VERSION ""
//Author: Matthew Nice

NS_ :

BS_:

BU_: XXX

BO_ 116 PEDAL_CMD: 12 XXX
 SG_ TORQUE_CMD_CCM : 86|12@0+ (1,0) [0|4000] "" XXX
 SG_ ACCEL_THROTTLE : 43|10@0+ (1,0) [0|4000] "" XXX
 SG_ ACCEL_PEDAL_DRIVER : 49|10@0+ (1,0) [0|4000] "" XXX

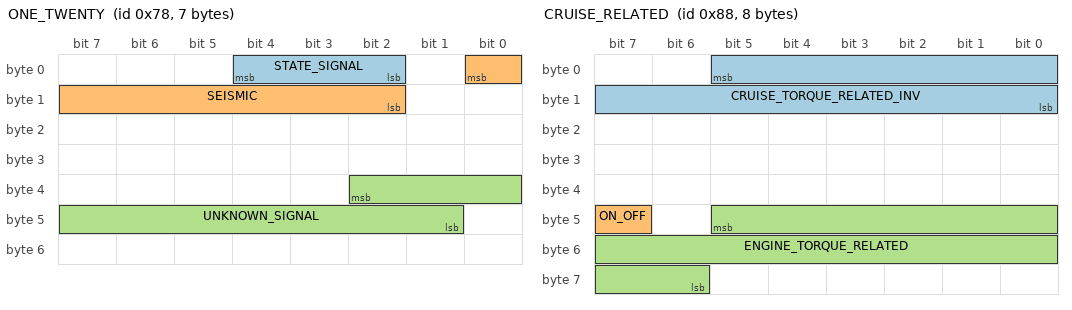
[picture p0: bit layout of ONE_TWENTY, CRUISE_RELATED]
BO_ 120 ONE_TWENTY: 7 XXX
 SG_ STATE_SIGNAL : 4|3@0+ (1,0) [0|4000] "" XXX
 SG_ SEISMIC : 0|7@0+ (1,0) [0|4000] "" XXX
 SG_ UNKNOWN_SIGNAL : 34|10@0+ (1,0) [0|4000] "" XXX

BO_ 136 CRUISE_RELATED: 8 XXX
 SG_ CRUISE_TORQUE_RELATED_INV : 5|14@0+ (1,0) [0|4000] "" XXX
 SG_ ON_OFF : 47|1@0+ (1,0) [0|1] "" XXX
 SG_ ENGINE_TORQUE_RELATED : 45|16@0+ (1,0) [0|50000] "" XXX

BO_ 139 STEER_ANGLE: 48 XXX
 SG_ STEER_ANGLE : 55|16@0+ (0.05,0) [0|500] "" XXX
 SG_ STEER_ANGLE_REPEAT : 208|16@0+ (0.05,0) [0|500] "" XXX

BO_ 140 PEDAL_THROTTLE: 48 XXX
 SG_ ACCEL_PEDAL_POSITION: 43|10@0+ (1,0) [0|1000] "" XXX
 SG_ ACCEL_PEDAL_POSITION_REPEAT: 49|10@0+ (1,0) [0|200] "" XXX
 SG_ RPM_RELATED: 86|12@0+ (0.05,0) [0|4000] "" XXX
 SG_ WHEEL_TORQUE_CMD_RELATED: 139|16@0+ (0.05,0) [0|100000] "" XXX
 SG_ RPM: 167|16@0+ (0.14285,0) [0|100000] "" XXX
 SG_ WHEEL_TORQUE_CMD_RELATED_2: 183|10@0+ (0.05,0) [0|100000] "" XXX

BO_ 141 STEERING_WHEEL: 24 XXX
 SG_ STEER_ANGLE: 55|18@0+ (1,0) [0|140000] "" XXX
 SG_ STEER_RATE: 66|12@0+ (1,0) [0|4000] "" XXX
 SG_ STEER_RELATED_YAW: 86|11@0+ (1,0) [0|1000] "" XXX

BO_ 168 STEERING_2: 24 XXX
 SG_ STEER_ANGLE: 55|12@0+ (1,0) [0|140000] "" XXX
 SG_ STEER_RATE: 79|16@0+ (1,0) [0|4000] "" XXX

BO_ 286 TWO_EIGHTY_SIX: 3 XXX
 SG_ WHEEL_TORQUE_CMD: 5|15@0+ (1,0) [0|100] "" XXX

BO_ 303 SPEED: 12 XXX
 SG_ GEAR: 55|6@0+ (1,0) [0|64] "" XXX
 SG_ WHEEL_TORQUE: 60|12@0+ (1,0) [0|4000] "" XXX
 SG_ SPEED : 77|12@0+ (0.048,0) [0|65535] "kph" XXX

BO_ 308 CRUISE: 64 XXX
 SG_ CRUISE_TORQUE_STATE : 57|4@0+ (1,0) [0|16] "" XXX
 SG_ WHEEL_TORQUE_CMD : 68|12@0+ (1,0) [0|4000] "" XXX
 SG_ STEER_ANGLE_BUT_NOT : 151|16@0+ (1,0) [0|40000] "" XXX
 SG_ BRAKE_TORQUE_ACTIVE : 160|1@0+ (1,0) [0|1] "" XXX
 SG_ BRAKE_TORQUE_CMD : 170|10@0+ (1,0) [0|1000] "" XXX
 SG_ CRUISE_STATE : 306|4@0+ (1,0) [0|32] "" XXX
 SG_ CRUISE_ENGAGED : 321|1@0+ (1,0) [0|1] "" XXX

BO_ 381 RADAR_SENSOR1: 64 XXX
 SG_ REPEATED_NON_DECREASING : 24|18@0+ (1,0) [0|200000] "" XXX

 SG_ REL_ACCEL1_VALID : 48|1@0+ (1,0) [0|1] "" XXX
 SG_ REL_ACCEL1 : 63|6@0+ (1,0) [0|200000] "" XXX

 SG_ FOURTH1_VALID : 57|1@0+ (1,0) [0|1] "" XXX
 SG_ FOURTH1: 56|13@0+ (0.03333,0) [0|200000] "" XXX

 //SG_ LEAD_DIST1_VALID : 82|1@0+ (1,0) [0|1] "" XXX
 SG_ LEAD_DIST1 : 82|12@0+ (0.1,0) [0|200000] "" XXX

 SG_ REL_VEL1 : 99|11@0- (0.2,2) [0|200000] "" XXX

 SG_ REL_ACCEL2 : 135|6@0+ (1,0) [0|200000] "" XXX
 SG_ FOURTH2 : 128|13@0+ (1,0) [0|200000] "" XXX
 SG_ LEAD_DIST2 : 154|12@0+ (0.1,0) [0|200000] "" XXX
 SG_ REL_VEL2 : 173|13@0+ (1,0) [0|200000] "" XXX

 SG_ BUTTON_PRESS0 : 124|1@0+ (1,0) [0|200000] "" XXX
 SG_ BUTTON_PRESS1 : 196|1@0+ (1,0) [0|200000] "" XXX
 SG_ BUTTON_PRESS2 : 268|1@0+ (1,0) [0|200000] "" XXX
 SG_ BUTTON_PRESS3 : 340|1@0+ (1,0) [0|200000] "" XXX
 SG_ BUTTON_PRESS4 : 412|1@0+ (1,0) [0|200000] "" XXX
 SG_ BUTTON_PRESS5 : 484|1@0+ (1,0) [0|200000] "" XXX

 SG_ REL_ACCEL3 : 207|6@0+ (1,0) [0|200000] "" XXX
 SG_ FOURTH3: 200|13@0+ (1,0) [0|200000] "" XXX
 SG_ LEAD_DIST3 : 226|12@0+ (0.1,0) [0|200000] "" XXX
 SG_ REL_VEL3 : 245|13@0+ (1,0) [0|200000] "" XXX

 SG_ REL_ACCEL4 : 279|6@0+ (1,0) [0|200000] "" XXX
 SG_ FOURTH4: 272|13@0+ (1,0) [0|200000] "" XXX
 SG_ LEAD_DIST4 : 298|12@0+ (0.1,0) [0|200000] "" XXX
 SG_ REL_VEL4 : 317|13@0+ (1,0) [0|200000] "" XXX

 SG_ REL_ACCEL5 : 351|6@0+ (1,0) [0|200000] "" XXX
 SG_ FOURTH5: 344|13@0+ (1,0) [0|200000] "" XXX
 SG_ LEAD_DIST5 : 370|12@0+ (0.1,0) [0|200000] "" XXX
 SG_ REL_VEL5 : 389|13@0+ (1,0) [0|200000] "" XXX

 SG_ REL_ACCEL6 : 423|6@0+ (1,0) [0|200000] "" XXX
 SG_ FOURTH6: 416|13@0+ (1,0) [0|200000] "" XXX
 SG_ LEAD_DIST6 : 442|12@0+ (0.1,0) [0|200000] "" XXX
 SG_ REL_VEL6 : 461|13@0+ (1,0) [0|200000] "" XXX

BO_ 382 RADAR_SENSOR2: 64 XXX
 SG_ REPEATED_NON_DECREASING : 24|18@0+ (1,0) [0|200000] "" XXX

 SG_ REL_ACCEL1_VALID : 48|1@0+ (1,0) [0|1] "" XXX
 SG_ REL_ACCEL1 : 63|6@0+ (1,0) [0|200000] "" XXX

 SG_ FOURTH1_VALID : 57|1@0+ (1,0) [0|1] "" XXX
 SG_ FOURTH1: 56|13@0+ (0.03333,0) [0|200000] "" XXX

 //SG_ LEAD_DIST1_VALID : 82|1@0+ (1,0) [0|1] "" XXX
 SG_ LEAD_DIST1 : 82|12@0+ (0.1,0) [0|200000] "" XXX

 SG_ REL_VEL1 : 99|11@0- (0.2,2) [0|200000] "" XXX

 SG_ REL_ACCEL2 : 135|6@0+ (1,0) [0|200000] "" XXX
 SG_ FOURTH2 : 128|13@0+ (1,0) [0|200000] "" XXX
 SG_ LEAD_DIST2 : 154|12@0+ (0.1,0) [0|200000] "" XXX
 SG_ REL_VEL2 : 173|13@0+ (1,0) [0|200000] "" XXX

 SG_ BUTTON_PRESS0 : 124|1@0+ (1,0) [0|200000] "" XXX
 SG_ BUTTON_PRESS1 : 196|1@0+ (1,0) [0|200000] "" XXX
 SG_ BUTTON_PRESS2 : 268|1@0+ (1,0) [0|200000] "" XXX
 SG_ BUTTON_PRESS3 : 340|1@0+ (1,0) [0|200000] "" XXX
 SG_ BUTTON_PRESS4 : 412|1@0+ (1,0) [0|200000] "" XXX
 SG_ BUTTON_PRESS5 : 484|1@0+ (1,0) [0|200000] "" XXX

 SG_ REL_ACCEL3 : 207|6@0+ (1,0) [0|200000] "" XXX
 SG_ FOURTH3: 200|13@0+ (1,0) [0|200000] "" XXX
 SG_ LEAD_DIST3 : 226|12@0+ (0.1,0) [0|200000] "" XXX
 SG_ REL_VEL3 : 245|13@0+ (1,0) [0|200000] "" XXX

 SG_ REL_ACCEL4 : 279|6@0+ (1,0) [0|200000] "" XXX
 SG_ FOURTH4: 272|13@0+ (1,0) [0|200000] "" XXX
 SG_ LEAD_DIST4 : 298|12@0+ (0.1,0) [0|200000] "" XXX
 SG_ REL_VEL4 : 317|13@0+ (1,0) [0|200000] "" XXX

 SG_ REL_ACCEL5 : 351|6@0+ (1,0) [0|200000] "" XXX
 SG_ FOURTH5: 344|13@0+ (1,0) [0|200000] "" XXX
 SG_ LEAD_DIST5 : 370|12@0+ (0.1,0) [0|200000] "" XXX
 SG_ REL_VEL5 : 389|13@0+ (1,0) [0|200000] "" XXX

 SG_ REL_ACCEL6 : 423|6@0+ (1,0) [0|200000] "" XXX
 SG_ FOURTH6: 416|13@0+ (1,0) [0|200000] "" XXX
 SG_ LEAD_DIST6 : 442|12@0+ (0.1,0) [0|200000] "" XXX
 SG_ REL_VEL6 : 461|13@0+ (1,0) [0|200000] "" XXX

BO_ 385 RADAR_SENSOR3: 64 XXX
 SG_ REPEATED_NON_DECREASING : 24|18@0+ (1,0) [0|200000] "" XXX

 SG_ REL_ACCEL1_VALID : 48|1@0+ (1,0) [0|1] "" XXX
 SG_ REL_ACCEL1 : 63|7@0+ (1,0) [0|200000] "" XXX

 SG_ FOURTH1_VALID : 56|1@0+ (1,0) [0|1] "" XXX
 SG_ FOURTH1: 71|12@0+ (1,0) [0|200000] "" XXX

 //SG_ LEAD_DIST1_VALID : 82|1@0+ (1,0) [0|1] "" XXX
 SG_ LEAD_DIST1 : 82|12@0+ (0.1,0) [0|200000] "" XXX

 SG_ REL_VEL1 : 99|11@0- (0.2,2) [0|200000] "" XXX

 SG_ REL_ACCEL2 : 135|6@0+ (1,0) [0|200000] "" XXX
 SG_ FOURTH2 : 128|13@0+ (1,0) [0|200000] "" XXX
 SG_ LEAD_DIST2 : 154|12@0+ (0.1,0) [0|200000] "" XXX
 SG_ REL_VEL2 : 173|13@0+ (1,0) [0|200000] "" XXX

 SG_ BUTTON_PRESS0 : 124|1@0+ (1,0) [0|200000] "" XXX
 SG_ BUTTON_PRESS1 : 196|1@0+ (1,0) [0|200000] "" XXX
 SG_ BUTTON_PRESS2 : 268|1@0+ (1,0) [0|200000] "" XXX
 SG_ BUTTON_PRESS3 : 340|1@0+ (1,0) [0|200000] "" XXX
 SG_ BUTTON_PRESS4 : 412|1@0+ (1,0) [0|200000] "" XXX
 SG_ BUTTON_PRESS5 : 484|1@0+ (1,0) [0|200000] "" XXX

 SG_ REL_ACCEL3 : 207|6@0+ (1,0) [0|200000] "" XXX
 SG_ FOURTH3: 200|13@0+ (1,0) [0|200000] "" XXX
 SG_ LEAD_DIST3 : 226|12@0+ (0.1,0) [0|200000] "" XXX
 SG_ REL_VEL3 : 245|13@0+ (1,0) [0|200000] "" XXX

 SG_ REL_ACCEL4 : 279|6@0+ (1,0) [0|200000] "" XXX
 SG_ FOURTH4: 272|13@0+ (1,0) [0|200000] "" XXX
 SG_ LEAD_DIST4 : 298|12@0+ (0.1,0) [0|200000] "" XXX
 SG_ REL_VEL4 : 317|13@0+ (1,0) [0|200000] "" XXX

 SG_ REL_ACCEL5 : 351|6@0+ (1,0) [0|200000] "" XXX
 SG_ FOURTH5: 344|13@0+ (1,0) [0|200000] "" XXX
 SG_ LEAD_DIST5 : 370|12@0+ (0.1,0) [0|200000] "" XXX
 SG_ REL_VEL5 : 389|13@0+ (1,0) [0|200000] "" XXX

 SG_ REL_ACCEL6 : 423|6@0+ (1,0) [0|200000] "" XXX
 SG_ FOURTH6: 416|13@0+ (1,0) [0|200000] "" XXX
 SG_ LEAD_DIST6 : 442|12@0+ (0.1,0) [0|200000] "" XXX
 SG_ REL_VEL6 : 461|13@0+ (1,0) [0|200000] "" XXX

BO_ 386 RADAR_SENSOR4: 64 XXX
 SG_ REPEATED_NON_DECREASING : 24|18@0+ (1,0) [0|200000] "" XXX

 SG_ REL_ACCEL1_VALID : 48|1@0+ (1,0) [0|1] "" XXX
 SG_ REL_ACCEL1 : 63|7@0+ (1,0) [0|200000] "" XXX

 SG_ FOURTH1_VALID : 56|1@0+ (1,0) [0|1] "" XXX
 SG_ FOURTH1: 71|12@0+ (1,0) [0|200000] "" XXX

 //SG_ LEAD_DIST1_VALID : 82|1@0+ (1,0) [0|1] "" XXX
 SG_ LEAD_DIST1 : 82|12@0+ (0.1,0) [0|200000] "" XXX

 SG_ REL_VEL1 : 99|11@0- (0.2,2) [0|200000] "" XXX

 SG_ REL_ACCEL2 : 135|6@0+ (1,0) [0|200000] "" XXX
 SG_ FOURTH2 : 128|13@0+ (1,0) [0|200000] "" XXX
 SG_ LEAD_DIST2 : 154|12@0+ (0.1,0) [0|200000] "" XXX
 SG_ REL_VEL2 : 173|13@0+ (1,0) [0|200000] "" XXX

 SG_ BUTTON_PRESS0 : 124|1@0+ (1,0) [0|200000] "" XXX
 SG_ BUTTON_PRESS1 : 196|1@0+ (1,0) [0|200000] "" XXX
 SG_ BUTTON_PRESS2 : 268|1@0+ (1,0) [0|200000] "" XXX
 SG_ BUTTON_PRESS3 : 340|1@0+ (1,0) [0|200000] "" XXX
 SG_ BUTTON_PRESS4 : 412|1@0+ (1,0) [0|200000] "" XXX
 SG_ BUTTON_PRESS5 : 484|1@0+ (1,0) [0|200000] "" XXX

 SG_ REL_ACCEL3 : 207|6@0+ (1,0) [0|200000] "" XXX
 SG_ FOURTH3: 200|13@0+ (1,0) [0|200000] "" XXX
 SG_ LEAD_DIST3 : 226|12@0+ (0.1,0) [0|200000] "" XXX
 SG_ REL_VEL3 : 245|13@0+ (1,0) [0|200000] "" XXX

 SG_ REL_ACCEL4 : 279|6@0+ (1,0) [0|200000] "" XXX
 SG_ FOURTH4: 272|13@0+ (1,0) [0|200000] "" XXX
 SG_ LEAD_DIST4 : 298|12@0+ (0.1,0) [0|200000] "" XXX
 SG_ REL_VEL4 : 317|13@0+ (1,0) [0|200000] "" XXX

 SG_ REL_ACCEL5 : 351|6@0+ (1,0) [0|200000] "" XXX
 SG_ FOURTH5: 344|13@0+ (1,0) [0|200000] "" XXX
 SG_ LEAD_DIST5 : 370|12@0+ (0.1,0) [0|200000] "" XXX
 SG_ REL_VEL5 : 389|13@0+ (1,0) [0|200000] "" XXX

 SG_ REL_ACCEL6 : 423|6@0+ (1,0) [0|200000] "" XXX
 SG_ FOURTH6: 416|13@0+ (1,0) [0|200000] "" XXX
 SG_ LEAD_DIST6 : 442|12@0+ (0.1,0) [0|200000] "" XXX
 SG_ REL_VEL6 : 461|13@0+ (1,0) [0|200000] "" XXX

BO_ 389 RADAR_SENSOR5: 64 XXX
 SG_ REPEATED_NON_DECREASING : 24|18@0+ (1,0) [0|200000] "" XXX

 SG_ REL_ACCEL1_VALID : 48|1@0+ (1,0) [0|1] "" XXX
 SG_ REL_ACCEL1 : 63|7@0+ (1,0) [0|200000] "" XXX

 SG_ FOURTH1_VALID : 56|1@0+ (1,0) [0|1] "" XXX
 SG_ FOURTH1: 71|12@0+ (1,0) [0|200000] "" XXX

 //SG_ LEAD_DIST1_VALID : 82|1@0+ (1,0) [0|1] "" XXX
 SG_ LEAD_DIST1 : 82|12@0+ (0.1,0) [0|200000] "" XXX

 SG_ REL_VEL1 : 99|11@0- (0.2,2) [0|200000] "" XXX

 SG_ REL_ACCEL2 : 135|6@0+ (1,0) [0|200000] "" XXX
 SG_ FOURTH2 : 128|13@0+ (1,0) [0|200000] "" XXX
 SG_ LEAD_DIST2 : 154|12@0+ (0.1,0) [0|200000] "" XXX
 SG_ REL_VEL2 : 173|13@0+ (1,0) [0|200000] "" XXX

 SG_ BUTTON_PRESS0 : 124|1@0+ (1,0) [0|200000] "" XXX
 SG_ BUTTON_PRESS1 : 196|1@0+ (1,0) [0|200000] "" XXX
 SG_ BUTTON_PRESS2 : 268|1@0+ (1,0) [0|200000] "" XXX
 SG_ BUTTON_PRESS3 : 340|1@0+ (1,0) [0|200000] "" XXX
 SG_ BUTTON_PRESS4 : 412|1@0+ (1,0) [0|200000] "" XXX
 SG_ BUTTON_PRESS5 : 484|1@0+ (1,0) [0|200000] "" XXX

 SG_ REL_ACCEL3 : 207|6@0+ (1,0) [0|200000] "" XXX
 SG_ FOURTH3: 200|13@0+ (1,0) [0|200000] "" XXX
 SG_ LEAD_DIST3 : 226|12@0+ (0.1,0) [0|200000] "" XXX
 SG_ REL_VEL3 : 245|13@0+ (1,0) [0|200000] "" XXX

 SG_ REL_ACCEL4 : 279|6@0+ (1,0) [0|200000] "" XXX
 SG_ FOURTH4: 272|13@0+ (1,0) [0|200000] "" XXX
 SG_ LEAD_DIST4 : 298|12@0+ (0.1,0) [0|200000] "" XXX
 SG_ REL_VEL4 : 317|13@0+ (1,0) [0|200000] "" XXX

 SG_ REL_ACCEL5 : 351|6@0+ (1,0) [0|200000] "" XXX
 SG_ FOURTH5: 344|13@0+ (1,0) [0|200000] "" XXX
 SG_ LEAD_DIST5 : 370|12@0+ (0.1,0) [0|200000] "" XXX
 SG_ REL_VEL5 : 389|13@0+ (1,0) [0|200000] "" XXX

 SG_ REL_ACCEL6 : 423|6@0+ (1,0) [0|200000] "" XXX
 SG_ FOURTH6: 416|13@0+ (1,0) [0|200000] "" XXX
 SG_ LEAD_DIST6 : 442|12@0+ (0.1,0) [0|200000] "" XXX
 SG_ REL_VEL6 : 461|13@0+ (1,0) [0|200000] "" XXX

BO_ 390 RADAR_SENSOR6: 64 XXX
 SG_ REPEATED_NON_DECREASING : 24|18@0+ (1,0) [0|200000] "" XXX

 SG_ REL_ACCEL1_VALID : 48|1@0+ (1,0) [0|1] "" XXX
 SG_ REL_ACCEL1 : 63|7@0+ (1,0) [0|200000] "" XXX

 SG_ FOURTH1_VALID : 56|1@0+ (1,0) [0|1] "" XXX
 SG_ FOURTH1: 71|12@0+ (1,0) [0|200000] "" XXX

 //SG_ LEAD_DIST1_VALID : 82|1@0+ (1,0) [0|1] "" XXX
 SG_ LEAD_DIST1 : 82|12@0+ (0.1,0) [0|200000] "" XXX

 SG_ REL_VEL1 : 99|11@0- (0.2,2) [0|200000] "" XXX

 SG_ REL_ACCEL2 : 135|6@0+ (1,0) [0|200000] "" XXX
 SG_ FOURTH2 : 128|13@0+ (1,0) [0|200000] "" XXX
 SG_ LEAD_DIST2 : 154|12@0+ (0.1,0) [0|200000] "" XXX
 SG_ REL_VEL2 : 173|13@0+ (1,0) [0|200000] "" XXX

 SG_ BUTTON_PRESS0 : 124|1@0+ (1,0) [0|200000] "" XXX
 SG_ BUTTON_PRESS1 : 196|1@0+ (1,0) [0|200000] "" XXX
 SG_ BUTTON_PRESS2 : 268|1@0+ (1,0) [0|200000] "" XXX
 SG_ BUTTON_PRESS3 : 340|1@0+ (1,0) [0|200000] "" XXX
 SG_ BUTTON_PRESS4 : 412|1@0+ (1,0) [0|200000] "" XXX
 SG_ BUTTON_PRESS5 : 484|1@0+ (1,0) [0|200000] "" XXX

 SG_ REL_ACCEL3 : 207|6@0+ (1,0) [0|200000] "" XXX
 SG_ FOURTH3: 200|13@0+ (1,0) [0|200000] "" XXX
 SG_ LEAD_DIST3 : 226|12@0+ (0.1,0) [0|200000] "" XXX
 SG_ REL_VEL3 : 245|13@0+ (1,0) [0|200000] "" XXX

 SG_ REL_ACCEL4 : 279|6@0+ (1,0) [0|200000] "" XXX
 SG_ FOURTH4: 272|13@0+ (1,0) [0|200000] "" XXX
 SG_ LEAD_DIST4 : 298|12@0+ (0.1,0) [0|200000] "" XXX
 SG_ REL_VEL4 : 317|13@0+ (1,0) [0|200000] "" XXX

 SG_ REL_ACCEL5 : 351|6@0+ (1,0) [0|200000] "" XXX
 SG_ FOURTH5: 344|13@0+ (1,0) [0|200000] "" XXX
 SG_ LEAD_DIST5 : 370|12@0+ (0.1,0) [0|200000] "" XXX
 SG_ REL_VEL5 : 389|13@0+ (1,0) [0|200000] "" XXX

 SG_ REL_ACCEL6 : 423|6@0+ (1,0) [0|200000] "" XXX
 SG_ FOURTH6: 416|13@0+ (1,0) [0|200000] "" XXX
 SG_ LEAD_DIST6 : 442|12@0+ (0.1,0) [0|200000] "" XXX
 SG_ REL_VEL6 : 461|13@0+ (1,0) [0|200000] "" XXX

BO_ 393 RADAR_SENSOR7: 64 XXX
 SG_ REPEATED_NON_DECREASING : 24|18@0+ (1,0) [0|200000] "" XXX

 SG_ REL_ACCEL1_VALID : 48|1@0+ (1,0) [0|1] "" XXX
 SG_ REL_ACCEL1 : 63|7@0+ (1,0) [0|200000] "" XXX

 SG_ FOURTH1_VALID : 56|1@0+ (1,0) [0|1] "" XXX
 SG_ FOURTH1: 71|12@0+ (1,0) [0|200000] "" XXX

 //SG_ LEAD_DIST1_VALID : 82|1@0+ (1,0) [0|1] "" XXX
 SG_ LEAD_DIST1 : 82|12@0+ (0.1,0) [0|200000] "" XXX

 SG_ REL_VEL1 : 99|11@0- (0.2,2) [0|200000] "" XXX

 SG_ REL_ACCEL2 : 135|6@0+ (1,0) [0|200000] "" XXX
 SG_ FOURTH2 : 128|13@0+ (1,0) [0|200000] "" XXX
 SG_ LEAD_DIST2 : 154|12@0+ (0.1,0) [0|200000] "" XXX
 SG_ REL_VEL2 : 173|13@0+ (1,0) [0|200000] "" XXX

 SG_ BUTTON_PRESS0 : 124|1@0+ (1,0) [0|200000] "" XXX
 SG_ BUTTON_PRESS1 : 196|1@0+ (1,0) [0|200000] "" XXX
 SG_ BUTTON_PRESS2 : 268|1@0+ (1,0) [0|200000] "" XXX
 SG_ BUTTON_PRESS3 : 340|1@0+ (1,0) [0|200000] "" XXX
 SG_ BUTTON_PRESS4 : 412|1@0+ (1,0) [0|200000] "" XXX
 SG_ BUTTON_PRESS5 : 484|1@0+ (1,0) [0|200000] "" XXX

 SG_ REL_ACCEL3 : 207|6@0+ (1,0) [0|200000] "" XXX
 SG_ FOURTH3: 200|13@0+ (1,0) [0|200000] "" XXX
 SG_ LEAD_DIST3 : 226|12@0+ (0.1,0) [0|200000] "" XXX
 SG_ REL_VEL3 : 245|13@0+ (1,0) [0|200000] "" XXX

 SG_ REL_ACCEL4 : 279|6@0+ (1,0) [0|200000] "" XXX
 SG_ FOURTH4: 272|13@0+ (1,0) [0|200000] "" XXX
 SG_ LEAD_DIST4 : 298|12@0+ (0.1,0) [0|200000] "" XXX
 SG_ REL_VEL4 : 317|13@0+ (1,0) [0|200000] "" XXX

 SG_ REL_ACCEL5 : 351|6@0+ (1,0) [0|200000] "" XXX
 SG_ FOURTH5: 344|13@0+ (1,0) [0|200000] "" XXX
 SG_ LEAD_DIST5 : 370|12@0+ (0.1,0) [0|200000] "" XXX
 SG_ REL_VEL5 : 389|13@0+ (1,0) [0|200000] "" XXX

 SG_ REL_ACCEL6 : 423|6@0+ (1,0) [0|200000] "" XXX
 SG_ FOURTH6: 416|13@0+ (1,0) [0|200000] "" XXX
 SG_ LEAD_DIST6 : 442|12@0+ (0.1,0) [0|200000] "" XXX
 SG_ REL_VEL6 : 461|13@0+ (1,0) [0|200000] "" XXX

BO_ 394 RADAR_SENSOR8: 64 XXX
 SG_ REPEATED_NON_DECREASING : 24|18@0+ (1,0) [0|200000] "" XXX

 SG_ REL_ACCEL1_VALID : 48|1@0+ (1,0) [0|1] "" XXX
 SG_ REL_ACCEL1 : 63|7@0+ (1,0) [0|200000] "" XXX

 SG_ FOURTH1_VALID : 56|1@0+ (1,0) [0|1] "" XXX
 SG_ FOURTH1: 71|12@0+ (1,0) [0|200000] "" XXX

 //SG_ LEAD_DIST1_VALID : 82|1@0+ (1,0) [0|1] "" XXX
 SG_ LEAD_DIST1 : 82|12@0+ (0.1,0) [0|200000] "" XXX

 SG_ REL_VEL1 : 99|11@0- (0.2,2) [0|200000] "" XXX

 SG_ REL_ACCEL2 : 135|6@0+ (1,0) [0|200000] "" XXX
 SG_ FOURTH2 : 128|13@0+ (1,0) [0|200000] "" XXX
 SG_ LEAD_DIST2 : 154|12@0+ (0.1,0) [0|200000] "" XXX
 SG_ REL_VEL2 : 173|13@0+ (1,0) [0|200000] "" XXX

 SG_ BUTTON_PRESS0 : 124|1@0+ (1,0) [0|200000] "" XXX
 SG_ BUTTON_PRESS1 : 196|1@0+ (1,0) [0|200000] "" XXX
 SG_ BUTTON_PRESS2 : 268|1@0+ (1,0) [0|200000] "" XXX
 SG_ BUTTON_PRESS3 : 340|1@0+ (1,0) [0|200000] "" XXX
 SG_ BUTTON_PRESS4 : 412|1@0+ (1,0) [0|200000] "" XXX
 SG_ BUTTON_PRESS5 : 484|1@0+ (1,0) [0|200000] "" XXX

 SG_ REL_ACCEL3 : 207|6@0+ (1,0) [0|200000] "" XXX
 SG_ FOURTH3: 200|13@0+ (1,0) [0|200000] "" XXX
 SG_ LEAD_DIST3 : 226|12@0+ (0.1,0) [0|200000] "" XXX
 SG_ REL_VEL3 : 245|13@0+ (1,0) [0|200000] "" XXX

 SG_ REL_ACCEL4 : 279|6@0+ (1,0) [0|200000] "" XXX
 SG_ FOURTH4: 272|13@0+ (1,0) [0|200000] "" XXX
 SG_ LEAD_DIST4 : 298|12@0+ (0.1,0) [0|200000] "" XXX
 SG_ REL_VEL4 : 317|13@0+ (1,0) [0|200000] "" XXX

 SG_ REL_ACCEL5 : 351|6@0+ (1,0) [0|200000] "" XXX
 SG_ FOURTH5: 344|13@0+ (1,0) [0|200000] "" XXX
 SG_ LEAD_DIST5 : 370|12@0+ (0.1,0) [0|200000] "" XXX
 SG_ REL_VEL5 : 389|13@0+ (1,0) [0|200000] "" XXX

 SG_ REL_ACCEL6 : 423|6@0+ (1,0) [0|200000] "" XXX
 SG_ FOURTH6: 416|13@0+ (1,0) [0|200000] "" XXX
 SG_ LEAD_DIST6 : 442|12@0+ (0.1,0) [0|200000] "" XXX
 SG_ REL_VEL6 : 461|13@0+ (1,0) [0|200000] "" XXX

BO_ 398 RADAR_SENSOR9: 64 XXX
 SG_ REPEATED_NON_DECREASING : 24|18@0+ (1,0) [0|200000] "" XXX

 SG_ REL_ACCEL1_VALID : 48|1@0+ (1,0) [0|1] "" XXX
 SG_ REL_ACCEL1 : 63|7@0+ (1,0) [0|200000] "" XXX

 SG_ FOURTH1_VALID : 56|1@0+ (1,0) [0|1] "" XXX
 SG_ FOURTH1: 71|12@0+ (1,0) [0|200000] "" XXX

 //SG_ LEAD_DIST1_VALID : 82|1@0+ (1,0) [0|1] "" XXX
 SG_ LEAD_DIST1 : 82|12@0+ (0.1,0) [0|200000] "" XXX

 SG_ REL_VEL1 : 99|11@0- (0.2,2) [0|200000] "" XXX

 SG_ REL_ACCEL2 : 135|6@0+ (1,0) [0|200000] "" XXX
 SG_ FOURTH2 : 128|13@0+ (1,0) [0|200000] "" XXX
 SG_ LEAD_DIST2 : 154|12@0+ (0.1,0) [0|200000] "" XXX
 SG_ REL_VEL2 : 173|13@0+ (1,0) [0|200000] "" XXX

 SG_ BUTTON_PRESS0 : 124|1@0+ (1,0) [0|200000] "" XXX
 SG_ BUTTON_PRESS1 : 196|1@0+ (1,0) [0|200000] "" XXX
 SG_ BUTTON_PRESS2 : 268|1@0+ (1,0) [0|200000] "" XXX
 SG_ BUTTON_PRESS3 : 340|1@0+ (1,0) [0|200000] "" XXX
 SG_ BUTTON_PRESS4 : 412|1@0+ (1,0) [0|200000] "" XXX
 SG_ BUTTON_PRESS5 : 484|1@0+ (1,0) [0|200000] "" XXX

 SG_ REL_ACCEL3 : 207|6@0+ (1,0) [0|200000] "" XXX
 SG_ FOURTH3: 200|13@0+ (1,0) [0|200000] "" XXX
 SG_ LEAD_DIST3 : 226|12@0+ (0.1,0) [0|200000] "" XXX
 SG_ REL_VEL3 : 245|13@0+ (1,0) [0|200000] "" XXX

 SG_ REL_ACCEL4 : 279|6@0+ (1,0) [0|200000] "" XXX
 SG_ FOURTH4: 272|13@0+ (1,0) [0|200000] "" XXX
 SG_ LEAD_DIST4 : 298|12@0+ (0.1,0) [0|200000] "" XXX
 SG_ REL_VEL4 : 317|13@0+ (1,0) [0|200000] "" XXX

 SG_ REL_ACCEL5 : 351|6@0+ (1,0) [0|200000] "" XXX
 SG_ FOURTH5: 344|13@0+ (1,0) [0|200000] "" XXX
 SG_ LEAD_DIST5 : 370|12@0+ (0.1,0) [0|200000] "" XXX
 SG_ REL_VEL5 : 389|13@0+ (1,0) [0|200000] "" XXX

 SG_ REL_ACCEL6 : 423|6@0+ (1,0) [0|200000] "" XXX
 SG_ FOURTH6: 416|13@0+ (1,0) [0|200000] "" XXX
 SG_ LEAD_DIST6 : 442|12@0+ (0.1,0) [0|200000] "" XXX
 SG_ REL_VEL6 : 461|13@0+ (1,0) [0|200000] "" XXX

BO_ 399 RADAR_SENSOR10: 64 XXX
 SG_ REPEATED_NON_DECREASING : 24|18@0+ (1,0) [0|200000] "" XXX

 SG_ REL_ACCEL1_VALID : 48|1@0+ (1,0) [0|1] "" XXX
 SG_ REL_ACCEL1 : 63|7@0+ (1,0) [0|200000] "" XXX

 SG_ FOURTH1_VALID : 56|1@0+ (1,0) [0|1] "" XXX
 SG_ FOURTH1: 71|12@0+ (1,0) [0|200000] "" XXX

 //SG_ LEAD_DIST1_VALID : 82|1@0+ (1,0) [0|1] "" XXX
 SG_ LEAD_DIST1 : 82|12@0+ (0.1,0) [0|200000] "" XXX

 SG_ REL_VEL1 : 99|11@0- (0.2,2) [0|200000] "" XXX

 SG_ REL_ACCEL2 : 135|6@0+ (1,0) [0|200000] "" XXX
 SG_ FOURTH2 : 128|13@0+ (1,0) [0|200000] "" XXX
 SG_ LEAD_DIST2 : 154|12@0+ (0.1,0) [0|200000] "" XXX
 SG_ REL_VEL2 : 173|13@0+ (1,0) [0|200000] "" XXX

 SG_ BUTTON_PRESS0 : 124|1@0+ (1,0) [0|200000] "" XXX
 SG_ BUTTON_PRESS1 : 196|1@0+ (1,0) [0|200000] "" XXX
 SG_ BUTTON_PRESS2 : 268|1@0+ (1,0) [0|200000] "" XXX
 SG_ BUTTON_PRESS3 : 340|1@0+ (1,0) [0|200000] "" XXX
 SG_ BUTTON_PRESS4 : 412|1@0+ (1,0) [0|200000] "" XXX
 SG_ BUTTON_PRESS5 : 484|1@0+ (1,0) [0|200000] "" XXX

 SG_ REL_ACCEL3 : 207|6@0+ (1,0) [0|200000] "" XXX
 SG_ FOURTH3: 200|13@0+ (1,0) [0|200000] "" XXX
 SG_ LEAD_DIST3 : 226|12@0+ (0.1,0) [0|200000] "" XXX
 SG_ REL_VEL3 : 245|13@0+ (1,0) [0|200000] "" XXX

 SG_ REL_ACCEL4 : 279|6@0+ (1,0) [0|200000] "" XXX
 SG_ FOURTH4: 272|13@0+ (1,0) [0|200000] "" XXX
 SG_ LEAD_DIST4 : 298|12@0+ (0.1,0) [0|200000] "" XXX
 SG_ REL_VEL4 : 317|13@0+ (1,0) [0|200000] "" XXX

 SG_ REL_ACCEL5 : 351|6@0+ (1,0) [0|200000] "" XXX
 SG_ FOURTH5: 344|13@0+ (1,0) [0|200000] "" XXX
 SG_ LEAD_DIST5 : 370|12@0+ (0.1,0) [0|200000] "" XXX
 SG_ REL_VEL5 : 389|13@0+ (1,0) [0|200000] "" XXX

 SG_ REL_ACCEL6 : 423|6@0+ (1,0) [0|200000] "" XXX
 SG_ FOURTH6: 416|13@0+ (1,0) [0|200000] "" XXX
 SG_ LEAD_DIST6 : 442|12@0+ (0.1,0) [0|200000] "" XXX
 SG_ REL_VEL6 : 461|13@0+ (1,0) [0|200000] "" XXX

BO_ 405 RADAR_SENSOR11: 64 XXX
 SG_ REPEATED_NON_DECREASING : 24|18@0+ (1,0) [0|200000] "" XXX

 SG_ REL_ACCEL1_VALID : 48|1@0+ (1,0) [0|1] "" XXX
 SG_ REL_ACCEL1 : 63|7@0+ (1,0) [0|200000] "" XXX

 SG_ FOURTH1_VALID : 56|1@0+ (1,0) [0|1] "" XXX
 SG_ FOURTH1: 71|12@0+ (1,0) [0|200000] "" XXX

 //SG_ LEAD_DIST1_VALID : 82|1@0+ (1,0) [0|1] "" XXX
 SG_ LEAD_DIST1 : 82|12@0+ (0.1,0) [0|200000] "" XXX

 SG_ REL_VEL1 : 99|11@0- (0.2,2) [0|200000] "" XXX

 SG_ REL_ACCEL2 : 135|6@0+ (1,0) [0|200000] "" XXX
 SG_ FOURTH2 : 128|13@0+ (1,0) [0|200000] "" XXX
 SG_ LEAD_DIST2 : 154|12@0+ (0.1,0) [0|200000] "" XXX
 SG_ REL_VEL2 : 173|13@0+ (1,0) [0|200000] "" XXX

 SG_ BUTTON_PRESS0 : 124|1@0+ (1,0) [0|200000] "" XXX
 SG_ BUTTON_PRESS1 : 196|1@0+ (1,0) [0|200000] "" XXX
 SG_ BUTTON_PRESS2 : 268|1@0+ (1,0) [0|200000] "" XXX
 SG_ BUTTON_PRESS3 : 340|1@0+ (1,0) [0|200000] "" XXX
 SG_ BUTTON_PRESS4 : 412|1@0+ (1,0) [0|200000] "" XXX
 SG_ BUTTON_PRESS5 : 484|1@0+ (1,0) [0|200000] "" XXX

 SG_ REL_ACCEL3 : 207|6@0+ (1,0) [0|200000] "" XXX
 SG_ FOURTH3: 200|13@0+ (1,0) [0|200000] "" XXX
 SG_ LEAD_DIST3 : 226|12@0+ (0.1,0) [0|200000] "" XXX
 SG_ REL_VEL3 : 245|13@0+ (1,0) [0|200000] "" XXX

 SG_ REL_ACCEL4 : 279|6@0+ (1,0) [0|200000] "" XXX
 SG_ FOURTH4: 272|13@0+ (1,0) [0|200000] "" XXX
 SG_ LEAD_DIST4 : 298|12@0+ (0.1,0) [0|200000] "" XXX
 SG_ REL_VEL4 : 317|13@0+ (1,0) [0|200000] "" XXX

 SG_ REL_ACCEL5 : 351|6@0+ (1,0) [0|200000] "" XXX
 SG_ FOURTH5: 344|13@0+ (1,0) [0|200000] "" XXX
 SG_ LEAD_DIST5 : 370|12@0+ (0.1,0) [0|200000] "" XXX
 SG_ REL_VEL5 : 389|13@0+ (1,0) [0|200000] "" XXX

 SG_ REL_ACCEL6 : 423|6@0+ (1,0) [0|200000] "" XXX
 SG_ FOURTH6: 416|13@0+ (1,0) [0|200000] "" XXX
 SG_ LEAD_DIST6 : 442|12@0+ (0.1,0) [0|200000] "" XXX
 SG_ REL_VEL6 : 461|13@0+ (1,0) [0|200000] "" XXX

BO_ 407 RADAR_SENSOR12: 64 XXX
 SG_ REPEATED_NON_DECREASING : 24|18@0+ (1,0) [0|200000] "" XXX

 SG_ REL_ACCEL1_VALID : 48|1@0+ (1,0) [0|1] "" XXX
 SG_ REL_ACCEL1 : 63|7@0+ (1,0) [0|200000] "" XXX

 SG_ FOURTH1_VALID : 56|1@0+ (1,0) [0|1] "" XXX
 SG_ FOURTH1: 71|12@0+ (1,0) [0|200000] "" XXX

 //SG_ LEAD_DIST1_VALID : 82|1@0+ (1,0) [0|1] "" XXX
 SG_ LEAD_DIST1 : 82|12@0+ (0.1,0) [0|200000] "" XXX

 SG_ REL_VEL1 : 99|11@0- (0.2,2) [0|200000] "" XXX

 SG_ REL_ACCEL2 : 135|6@0+ (1,0) [0|200000] "" XXX
 SG_ FOURTH2 : 128|13@0+ (1,0) [0|200000] "" XXX
 SG_ LEAD_DIST2 : 154|12@0+ (0.1,0) [0|200000] "" XXX
 SG_ REL_VEL2 : 173|13@0+ (1,0) [0|200000] "" XXX

 SG_ BUTTON_PRESS0 : 124|1@0+ (1,0) [0|200000] "" XXX
 SG_ BUTTON_PRESS1 : 196|1@0+ (1,0) [0|200000] "" XXX
 SG_ BUTTON_PRESS2 : 268|1@0+ (1,0) [0|200000] "" XXX
 SG_ BUTTON_PRESS3 : 340|1@0+ (1,0) [0|200000] "" XXX
 SG_ BUTTON_PRESS4 : 412|1@0+ (1,0) [0|200000] "" XXX
 SG_ BUTTON_PRESS5 : 484|1@0+ (1,0) [0|200000] "" XXX

 SG_ REL_ACCEL3 : 207|6@0+ (1,0) [0|200000] "" XXX
 SG_ FOURTH3: 200|13@0+ (1,0) [0|200000] "" XXX
 SG_ LEAD_DIST3 : 226|12@0+ (0.1,0) [0|200000] "" XXX
 SG_ REL_VEL3 : 245|13@0+ (1,0) [0|200000] "" XXX

 SG_ REL_ACCEL4 : 279|6@0+ (1,0) [0|200000] "" XXX
 SG_ FOURTH4: 272|13@0+ (1,0) [0|200000] "" XXX
 SG_ LEAD_DIST4 : 298|12@0+ (0.1,0) [0|200000] "" XXX
 SG_ REL_VEL4 : 317|13@0+ (1,0) [0|200000] "" XXX

 SG_ REL_ACCEL5 : 351|6@0+ (1,0) [0|200000] "" XXX
 SG_ FOURTH5: 344|13@0+ (1,0) [0|200000] "" XXX
 SG_ LEAD_DIST5 : 370|12@0+ (0.1,0) [0|200000] "" XXX
 SG_ REL_VEL5 : 389|13@0+ (1,0) [0|200000] "" XXX

 SG_ REL_ACCEL6 : 423|6@0+ (1,0) [0|200000] "" XXX
 SG_ FOURTH6: 416|13@0+ (1,0) [0|200000] "" XXX
 SG_ LEAD_DIST6 : 442|12@0+ (0.1,0) [0|200000] "" XXX
 SG_ REL_VEL6 : 461|13@0+ (1,0) [0|200000] "" XXX

BO_ 411 RADAR_SENSOR13: 64 XXX
 SG_ REPEATED_NON_DECREASING : 24|18@0+ (1,0) [0|200000] "" XXX

 SG_ REL_ACCEL1_VALID : 48|1@0+ (1,0) [0|1] "" XXX
 SG_ REL_ACCEL1 : 63|7@0+ (1,0) [0|200000] "" XXX

 SG_ FOURTH1_VALID : 56|1@0+ (1,0) [0|1] "" XXX
 SG_ FOURTH1: 71|12@0+ (1,0) [0|200000] "" XXX

 //SG_ LEAD_DIST1_VALID : 82|1@0+ (1,0) [0|1] "" XXX
 SG_ LEAD_DIST1 : 82|12@0+ (0.1,0) [0|200000] "" XXX

 SG_ REL_VEL1 : 99|11@0- (0.2,2) [0|200000] "" XXX

 SG_ REL_ACCEL2 : 135|6@0+ (1,0) [0|200000] "" XXX
 SG_ FOURTH2 : 128|13@0+ (1,0) [0|200000] "" XXX
 SG_ LEAD_DIST2 : 154|12@0+ (0.1,0) [0|200000] "" XXX
 SG_ REL_VEL2 : 173|13@0+ (1,0) [0|200000] "" XXX

 SG_ BUTTON_PRESS0 : 124|1@0+ (1,0) [0|200000] "" XXX
 SG_ BUTTON_PRESS1 : 196|1@0+ (1,0) [0|200000] "" XXX
 SG_ BUTTON_PRESS2 : 268|1@0+ (1,0) [0|200000] "" XXX
 SG_ BUTTON_PRESS3 : 340|1@0+ (1,0) [0|200000] "" XXX
 SG_ BUTTON_PRESS4 : 412|1@0+ (1,0) [0|200000] "" XXX
 SG_ BUTTON_PRESS5 : 484|1@0+ (1,0) [0|200000] "" XXX

 SG_ REL_ACCEL3 : 207|6@0+ (1,0) [0|200000] "" XXX
 SG_ FOURTH3: 200|13@0+ (1,0) [0|200000] "" XXX
 SG_ LEAD_DIST3 : 226|12@0+ (0.1,0) [0|200000] "" XXX
 SG_ REL_VEL3 : 245|13@0+ (1,0) [0|200000] "" XXX

 SG_ REL_ACCEL4 : 279|6@0+ (1,0) [0|200000] "" XXX
 SG_ FOURTH4: 272|13@0+ (1,0) [0|200000] "" XXX
 SG_ LEAD_DIST4 : 298|12@0+ (0.1,0) [0|200000] "" XXX
 SG_ REL_VEL4 : 317|13@0+ (1,0) [0|200000] "" XXX

 SG_ REL_ACCEL5 : 351|6@0+ (1,0) [0|200000] "" XXX
 SG_ FOURTH5: 344|13@0+ (1,0) [0|200000] "" XXX
 SG_ LEAD_DIST5 : 370|12@0+ (0.1,0) [0|200000] "" XXX
 SG_ REL_VEL5 : 389|13@0+ (1,0) [0|200000] "" XXX

 SG_ REL_ACCEL6 : 423|6@0+ (1,0) [0|200000] "" XXX
 SG_ FOURTH6: 416|13@0+ (1,0) [0|200000] "" XXX
 SG_ LEAD_DIST6 : 442|12@0+ (0.1,0) [0|200000] "" XXX
 SG_ REL_VEL6 : 461|13@0+ (1,0) [0|200000] "" XXX

BO_ 412 RADAR_SENSOR14: 64 XXX
 SG_ REPEATED_NON_DECREASING : 24|18@0+ (1,0) [0|200000] "" XXX

 SG_ REL_ACCEL1_VALID : 48|1@0+ (1,0) [0|1] "" XXX
 SG_ REL_ACCEL1 : 63|7@0+ (1,0) [0|200000] "" XXX

 SG_ FOURTH1_VALID : 56|1@0+ (1,0) [0|1] "" XXX
 SG_ FOURTH1: 71|12@0+ (1,0) [0|200000] "" XXX

 //SG_ LEAD_DIST1_VALID : 82|1@0+ (1,0) [0|1] "" XXX
 SG_ LEAD_DIST1 : 82|12@0+ (0.1,0) [0|200000] "" XXX

 SG_ REL_VEL1 : 99|11@0- (0.2,2) [0|200000] "" XXX

 SG_ REL_ACCEL2 : 135|6@0+ (1,0) [0|200000] "" XXX
 SG_ FOURTH2 : 128|13@0+ (1,0) [0|200000] "" XXX
 SG_ LEAD_DIST2 : 154|12@0+ (0.1,0) [0|200000] "" XXX
 SG_ REL_VEL2 : 173|13@0+ (1,0) [0|200000] "" XXX

 SG_ BUTTON_PRESS0 : 124|1@0+ (1,0) [0|200000] "" XXX
 SG_ BUTTON_PRESS1 : 196|1@0+ (1,0) [0|200000] "" XXX
 SG_ BUTTON_PRESS2 : 268|1@0+ (1,0) [0|200000] "" XXX
 SG_ BUTTON_PRESS3 : 340|1@0+ (1,0) [0|200000] "" XXX
 SG_ BUTTON_PRESS4 : 412|1@0+ (1,0) [0|200000] "" XXX
 SG_ BUTTON_PRESS5 : 484|1@0+ (1,0) [0|200000] "" XXX

 SG_ REL_ACCEL3 : 207|6@0+ (1,0) [0|200000] "" XXX
 SG_ FOURTH3: 200|13@0+ (1,0) [0|200000] "" XXX
 SG_ LEAD_DIST3 : 226|12@0+ (0.1,0) [0|200000] "" XXX
 SG_ REL_VEL3 : 245|13@0+ (1,0) [0|200000] "" XXX

 SG_ REL_ACCEL4 : 279|6@0+ (1,0) [0|200000] "" XXX
 SG_ FOURTH4: 272|13@0+ (1,0) [0|200000] "" XXX
 SG_ LEAD_DIST4 : 298|12@0+ (0.1,0) [0|200000] "" XXX
 SG_ REL_VEL4 : 317|13@0+ (1,0) [0|200000] "" XXX

 SG_ REL_ACCEL5 : 351|6@0+ (1,0) [0|200000] "" XXX
 SG_ FOURTH5: 344|13@0+ (1,0) [0|200000] "" XXX
 SG_ LEAD_DIST5 : 370|12@0+ (0.1,0) [0|200000] "" XXX
 SG_ REL_VEL5 : 389|13@0+ (1,0) [0|200000] "" XXX

 SG_ REL_ACCEL6 : 423|6@0+ (1,0) [0|200000] "" XXX
 SG_ FOURTH6: 416|13@0+ (1,0) [0|200000] "" XXX
 SG_ LEAD_DIST6 : 442|12@0+ (0.1,0) [0|200000] "" XXX
 SG_ REL_VEL6 : 461|13@0+ (1,0) [0|200000] "" XXX

BO_ 415 RADAR_SENSOR15: 64 XXX
 SG_ REPEATED_NON_DECREASING : 24|18@0+ (1,0) [0|200000] "" XXX

 SG_ REL_ACCEL1_VALID : 48|1@0+ (1,0) [0|1] "" XXX
 SG_ REL_ACCEL1 : 63|7@0+ (1,0) [0|200000] "" XXX

 SG_ FOURTH1_VALID : 56|1@0+ (1,0) [0|1] "" XXX
 SG_ FOURTH1: 71|12@0+ (1,0) [0|200000] "" XXX

 //SG_ LEAD_DIST1_VALID : 82|1@0+ (1,0) [0|1] "" XXX
 SG_ LEAD_DIST1 : 82|12@0+ (0.1,0) [0|200000] "" XXX

 SG_ REL_VEL1 : 99|11@0- (0.2,2) [0|200000] "" XXX

 SG_ REL_ACCEL2 : 135|6@0+ (1,0) [0|200000] "" XXX
 SG_ FOURTH2 : 128|13@0+ (1,0) [0|200000] "" XXX
 SG_ LEAD_DIST2 : 154|12@0+ (0.1,0) [0|200000] "" XXX
 SG_ REL_VEL2 : 173|13@0+ (1,0) [0|200000] "" XXX

 SG_ BUTTON_PRESS0 : 124|1@0+ (1,0) [0|200000] "" XXX
 SG_ BUTTON_PRESS1 : 196|1@0+ (1,0) [0|200000] "" XXX
 SG_ BUTTON_PRESS2 : 268|1@0+ (1,0) [0|200000] "" XXX
 SG_ BUTTON_PRESS3 : 340|1@0+ (1,0) [0|200000] "" XXX
 SG_ BUTTON_PRESS4 : 412|1@0+ (1,0) [0|200000] "" XXX
 SG_ BUTTON_PRESS5 : 484|1@0+ (1,0) [0|200000] "" XXX

 SG_ REL_ACCEL3 : 207|6@0+ (1,0) [0|200000] "" XXX
 SG_ FOURTH3: 200|13@0+ (1,0) [0|200000] "" XXX
 SG_ LEAD_DIST3 : 226|12@0+ (0.1,0) [0|200000] "" XXX
 SG_ REL_VEL3 : 245|13@0+ (1,0) [0|200000] "" XXX

 SG_ REL_ACCEL4 : 279|6@0+ (1,0) [0|200000] "" XXX
 SG_ FOURTH4: 272|13@0+ (1,0) [0|200000] "" XXX
 SG_ LEAD_DIST4 : 298|12@0+ (0.1,0) [0|200000] "" XXX
 SG_ REL_VEL4 : 317|13@0+ (1,0) [0|200000] "" XXX

 SG_ REL_ACCEL5 : 351|6@0+ (1,0) [0|200000] "" XXX
 SG_ FOURTH5: 344|13@0+ (1,0) [0|200000] "" XXX
 SG_ LEAD_DIST5 : 370|12@0+ (0.1,0) [0|200000] "" XXX
 SG_ REL_VEL5 : 389|13@0+ (1,0) [0|200000] "" XXX

 SG_ REL_ACCEL6 : 423|6@0+ (1,0) [0|200000] "" XXX
 SG_ FOURTH6: 416|13@0+ (1,0) [0|200000] "" XXX
 SG_ LEAD_DIST6 : 442|12@0+ (0.1,0) [0|200000] "" XXX
 SG_ REL_VEL6 : 461|13@0+ (1,0) [0|200000] "" XXX

BO_ 416 RADAR_SENSOR16: 64 XXX
 SG_ REPEATED_NON_DECREASING : 24|18@0+ (1,0) [0|200000] "" XXX

 SG_ REL_ACCEL1_VALID : 48|1@0+ (1,0) [0|1] "" XXX
 SG_ REL_ACCEL1 : 63|7@0+ (1,0) [0|200000] "" XXX

 SG_ FOURTH1_VALID : 56|1@0+ (1,0) [0|1] "" XXX
 SG_ FOURTH1: 71|12@0+ (1,0) [0|200000] "" XXX

 //SG_ LEAD_DIST1_VALID : 82|1@0+ (1,0) [0|1] "" XXX
 SG_ LEAD_DIST1 : 82|12@0+ (0.1,0) [0|200000] "" XXX

 SG_ REL_VEL1 : 99|11@0- (0.2,2) [0|200000] "" XXX

 SG_ REL_ACCEL2 : 135|6@0+ (1,0) [0|200000] "" XXX
 SG_ FOURTH2 : 128|13@0+ (1,0) [0|200000] "" XXX
 SG_ LEAD_DIST2 : 154|12@0+ (0.1,0) [0|200000] "" XXX
 SG_ REL_VEL2 : 173|13@0+ (1,0) [0|200000] "" XXX

 SG_ BUTTON_PRESS0 : 124|1@0+ (1,0) [0|200000] "" XXX
 SG_ BUTTON_PRESS1 : 196|1@0+ (1,0) [0|200000] "" XXX
 SG_ BUTTON_PRESS2 : 268|1@0+ (1,0) [0|200000] "" XXX
 SG_ BUTTON_PRESS3 : 340|1@0+ (1,0) [0|200000] "" XXX
 SG_ BUTTON_PRESS4 : 412|1@0+ (1,0) [0|200000] "" XXX
 SG_ BUTTON_PRESS5 : 484|1@0+ (1,0) [0|200000] "" XXX

 SG_ REL_ACCEL3 : 207|6@0+ (1,0) [0|200000] "" XXX
 SG_ FOURTH3: 200|13@0+ (1,0) [0|200000] "" XXX
 SG_ LEAD_DIST3 : 226|12@0+ (0.1,0) [0|200000] "" XXX
 SG_ REL_VEL3 : 245|13@0+ (1,0) [0|200000] "" XXX

 SG_ REL_ACCEL4 : 279|6@0+ (1,0) [0|200000] "" XXX
 SG_ FOURTH4: 272|13@0+ (1,0) [0|200000] "" XXX
 SG_ LEAD_DIST4 : 298|12@0+ (0.1,0) [0|200000] "" XXX
 SG_ REL_VEL4 : 317|13@0+ (1,0) [0|200000] "" XXX

 SG_ REL_ACCEL5 : 351|6@0+ (1,0) [0|200000] "" XXX
 SG_ FOURTH5: 344|13@0+ (1,0) [0|200000] "" XXX
 SG_ LEAD_DIST5 : 370|12@0+ (0.1,0) [0|200000] "" XXX
 SG_ REL_VEL5 : 389|13@0+ (1,0) [0|200000] "" XXX

 SG_ REL_ACCEL6 : 423|6@0+ (1,0) [0|200000] "" XXX
 SG_ FOURTH6: 416|13@0+ (1,0) [0|200000] "" XXX
 SG_ LEAD_DIST6 : 442|12@0+ (0.1,0) [0|200000] "" XXX
 SG_ REL_VEL6 : 461|13@0+ (1,0) [0|200000] "" XXX

BO_ 419 RADAR_SENSOR17: 64 XXX
 SG_ REPEATED_NON_DECREASING : 24|18@0+ (1,0) [0|200000] "" XXX

 SG_ REL_ACCEL1_VALID : 48|1@0+ (1,0) [0|1] "" XXX
 SG_ REL_ACCEL1 : 63|7@0+ (1,0) [0|200000] "" XXX

 SG_ FOURTH1_VALID : 56|1@0+ (1,0) [0|1] "" XXX
 SG_ FOURTH1: 71|12@0+ (1,0) [0|200000] "" XXX

 //SG_ LEAD_DIST1_VALID : 82|1@0+ (1,0) [0|1] "" XXX
 SG_ LEAD_DIST1 : 82|12@0+ (0.1,0) [0|200000] "" XXX

 SG_ REL_VEL1 : 99|11@0- (0.2,2) [0|200000] "" XXX

 SG_ REL_ACCEL2 : 135|6@0+ (1,0) [0|200000] "" XXX
 SG_ FOURTH2 : 128|13@0+ (1,0) [0|200000] "" XXX
 SG_ LEAD_DIST2 : 154|12@0+ (0.1,0) [0|200000] "" XXX
 SG_ REL_VEL2 : 173|13@0+ (1,0) [0|200000] "" XXX

 SG_ BUTTON_PRESS0 : 124|1@0+ (1,0) [0|200000] "" XXX
 SG_ BUTTON_PRESS1 : 196|1@0+ (1,0) [0|200000] "" XXX
 SG_ BUTTON_PRESS2 : 268|1@0+ (1,0) [0|200000] "" XXX
 SG_ BUTTON_PRESS3 : 340|1@0+ (1,0) [0|200000] "" XXX
 SG_ BUTTON_PRESS4 : 412|1@0+ (1,0) [0|200000] "" XXX
 SG_ BUTTON_PRESS5 : 484|1@0+ (1,0) [0|200000] "" XXX

 SG_ REL_ACCEL3 : 207|6@0+ (1,0) [0|200000] "" XXX
 SG_ FOURTH3: 200|13@0+ (1,0) [0|200000] "" XXX
 SG_ LEAD_DIST3 : 226|12@0+ (0.1,0) [0|200000] "" XXX
 SG_ REL_VEL3 : 245|13@0+ (1,0) [0|200000] "" XXX

 SG_ REL_ACCEL4 : 279|6@0+ (1,0) [0|200000] "" XXX
 SG_ FOURTH4: 272|13@0+ (1,0) [0|200000] "" XXX
 SG_ LEAD_DIST4 : 298|12@0+ (0.1,0) [0|200000] "" XXX
 SG_ REL_VEL4 : 317|13@0+ (1,0) [0|200000] "" XXX

 SG_ REL_ACCEL5 : 351|6@0+ (1,0) [0|200000] "" XXX
 SG_ FOURTH5: 344|13@0+ (1,0) [0|200000] "" XXX
 SG_ LEAD_DIST5 : 370|12@0+ (0.1,0) [0|200000] "" XXX
 SG_ REL_VEL5 : 389|13@0+ (1,0) [0|200000] "" XXX

 SG_ REL_ACCEL6 : 423|6@0+ (1,0) [0|200000] "" XXX
 SG_ FOURTH6: 416|13@0+ (1,0) [0|200000] "" XXX
 SG_ LEAD_DIST6 : 442|12@0+ (0.1,0) [0|200000] "" XXX
 SG_ REL_VEL6 : 461|13@0+ (1,0) [0|200000] "" XXX

BO_ 420 RADAR_SENSOR18: 64 XXX
 SG_ REPEATED_NON_DECREASING : 24|18@0+ (1,0) [0|200000] "" XXX

 SG_ REL_ACCEL1_VALID : 48|1@0+ (1,0) [0|1] "" XXX
 SG_ REL_ACCEL1 : 63|7@0+ (1,0) [0|200000] "" XXX

 SG_ FOURTH1_VALID : 56|1@0+ (1,0) [0|1] "" XXX
 SG_ FOURTH1: 71|12@0+ (1,0) [0|200000] "" XXX

 //SG_ LEAD_DIST1_VALID : 82|1@0+ (1,0) [0|1] "" XXX
 SG_ LEAD_DIST1 : 82|12@0+ (0.1,0) [0|200000] "" XXX

 SG_ REL_VEL1 : 99|11@0- (0.2,2) [0|200000] "" XXX

 SG_ REL_ACCEL2 : 135|6@0+ (1,0) [0|200000] "" XXX
 SG_ FOURTH2 : 128|13@0+ (1,0) [0|200000] "" XXX
 SG_ LEAD_DIST2 : 154|12@0+ (0.1,0) [0|200000] "" XXX
 SG_ REL_VEL2 : 173|13@0+ (1,0) [0|200000] "" XXX

 SG_ BUTTON_PRESS0 : 124|1@0+ (1,0) [0|200000] "" XXX
 SG_ BUTTON_PRESS1 : 196|1@0+ (1,0) [0|200000] "" XXX
 SG_ BUTTON_PRESS2 : 268|1@0+ (1,0) [0|200000] "" XXX
 SG_ BUTTON_PRESS3 : 340|1@0+ (1,0) [0|200000] "" XXX
 SG_ BUTTON_PRESS4 : 412|1@0+ (1,0) [0|200000] "" XXX
 SG_ BUTTON_PRESS5 : 484|1@0+ (1,0) [0|200000] "" XXX

 SG_ REL_ACCEL3 : 207|6@0+ (1,0) [0|200000] "" XXX
 SG_ FOURTH3: 200|13@0+ (1,0) [0|200000] "" XXX
 SG_ LEAD_DIST3 : 226|12@0+ (0.1,0) [0|200000] "" XXX
 SG_ REL_VEL3 : 245|13@0+ (1,0) [0|200000] "" XXX

 SG_ REL_ACCEL4 : 279|6@0+ (1,0) [0|200000] "" XXX
 SG_ FOURTH4: 272|13@0+ (1,0) [0|200000] "" XXX
 SG_ LEAD_DIST4 : 298|12@0+ (0.1,0) [0|200000] "" XXX
 SG_ REL_VEL4 : 317|13@0+ (1,0) [0|200000] "" XXX

 SG_ REL_ACCEL5 : 351|6@0+ (1,0) [0|200000] "" XXX
 SG_ FOURTH5: 344|13@0+ (1,0) [0|200000] "" XXX
 SG_ LEAD_DIST5 : 370|12@0+ (0.1,0) [0|200000] "" XXX
 SG_ REL_VEL5 : 389|13@0+ (1,0) [0|200000] "" XXX

 SG_ REL_ACCEL6 : 423|6@0+ (1,0) [0|200000] "" XXX
 SG_ FOURTH6: 416|13@0+ (1,0) [0|200000] "" XXX
 SG_ LEAD_DIST6 : 442|12@0+ (0.1,0) [0|200000] "" XXX
 SG_ REL_VEL6 : 461|13@0+ (1,0) [0|200000] "" XXX

BO_ 423 RADAR_SENSOR19: 64 XXX
 SG_ REPEATED_NON_DECREASING : 24|18@0+ (1,0) [0|200000] "" XXX

 SG_ REL_ACCEL1_VALID : 48|1@0+ (1,0) [0|1] "" XXX
 SG_ REL_ACCEL1 : 63|7@0+ (1,0) [0|200000] "" XXX

 SG_ FOURTH1_VALID : 56|1@0+ (1,0) [0|1] "" XXX
 SG_ FOURTH1: 71|12@0+ (1,0) [0|200000] "" XXX

 //SG_ LEAD_DIST1_VALID : 82|1@0+ (1,0) [0|1] "" XXX
 SG_ LEAD_DIST1 : 82|12@0+ (0.1,0) [0|200000] "" XXX

 SG_ REL_VEL1 : 99|11@0- (0.2,2) [0|200000] "" XXX

 SG_ REL_ACCEL2 : 135|6@0+ (1,0) [0|200000] "" XXX
 SG_ FOURTH2 : 128|13@0+ (1,0) [0|200000] "" XXX
 SG_ LEAD_DIST2 : 154|12@0+ (0.1,0) [0|200000] "" XXX
 SG_ REL_VEL2 : 173|13@0+ (1,0) [0|200000] "" XXX

 SG_ BUTTON_PRESS0 : 124|1@0+ (1,0) [0|200000] "" XXX
 SG_ BUTTON_PRESS1 : 196|1@0+ (1,0) [0|200000] "" XXX
 SG_ BUTTON_PRESS2 : 268|1@0+ (1,0) [0|200000] "" XXX
 SG_ BUTTON_PRESS3 : 340|1@0+ (1,0) [0|200000] "" XXX
 SG_ BUTTON_PRESS4 : 412|1@0+ (1,0) [0|200000] "" XXX
 SG_ BUTTON_PRESS5 : 484|1@0+ (1,0) [0|200000] "" XXX

 SG_ REL_ACCEL3 : 207|6@0+ (1,0) [0|200000] "" XXX
 SG_ FOURTH3: 200|13@0+ (1,0) [0|200000] "" XXX
 SG_ LEAD_DIST3 : 226|12@0+ (0.1,0) [0|200000] "" XXX
 SG_ REL_VEL3 : 245|13@0+ (1,0) [0|200000] "" XXX

 SG_ REL_ACCEL4 : 279|6@0+ (1,0) [0|200000] "" XXX
 SG_ FOURTH4: 272|13@0+ (1,0) [0|200000] "" XXX
 SG_ LEAD_DIST4 : 298|12@0+ (0.1,0) [0|200000] "" XXX
 SG_ REL_VEL4 : 317|13@0+ (1,0) [0|200000] "" XXX

 SG_ REL_ACCEL5 : 351|6@0+ (1,0) [0|200000] "" XXX
 SG_ FOURTH5: 344|13@0+ (1,0) [0|200000] "" XXX
 SG_ LEAD_DIST5 : 370|12@0+ (0.1,0) [0|200000] "" XXX
 SG_ REL_VEL5 : 389|13@0+ (1,0) [0|200000] "" XXX

 SG_ REL_ACCEL6 : 423|6@0+ (1,0) [0|200000] "" XXX
 SG_ FOURTH6: 416|13@0+ (1,0) [0|200000] "" XXX
 SG_ LEAD_DIST6 : 442|12@0+ (0.1,0) [0|200000] "" XXX
 SG_ REL_VEL6 : 461|13@0+ (1,0) [0|200000] "" XXX

BO_ 425 RADAR_SENSOR20: 64 XXX
 SG_ REPEATED_NON_DECREASING : 24|18@0+ (1,0) [0|200000] "" XXX

 SG_ REL_ACCEL1_VALID : 48|1@0+ (1,0) [0|1] "" XXX
 SG_ REL_ACCEL1 : 63|7@0+ (1,0) [0|200000] "" XXX

 SG_ FOURTH1_VALID : 56|1@0+ (1,0) [0|1] "" XXX
 SG_ FOURTH1: 71|12@0+ (1,0) [0|200000] "" XXX

 //SG_ LEAD_DIST1_VALID : 82|1@0+ (1,0) [0|1] "" XXX
 SG_ LEAD_DIST1 : 82|12@0+ (0.1,0) [0|200000] "" XXX

 SG_ REL_VEL1 : 99|11@0- (0.2,2) [0|200000] "" XXX

 SG_ REL_ACCEL2 : 135|6@0+ (1,0) [0|200000] "" XXX
 SG_ FOURTH2 : 128|13@0+ (1,0) [0|200000] "" XXX
 SG_ LEAD_DIST2 : 154|12@0+ (0.1,0) [0|200000] "" XXX
 SG_ REL_VEL2 : 173|13@0+ (1,0) [0|200000] "" XXX

 SG_ BUTTON_PRESS0 : 124|1@0+ (1,0) [0|200000] "" XXX
 SG_ BUTTON_PRESS1 : 196|1@0+ (1,0) [0|200000] "" XXX
 SG_ BUTTON_PRESS2 : 268|1@0+ (1,0) [0|200000] "" XXX
 SG_ BUTTON_PRESS3 : 340|1@0+ (1,0) [0|200000] "" XXX
 SG_ BUTTON_PRESS4 : 412|1@0+ (1,0) [0|200000] "" XXX
 SG_ BUTTON_PRESS5 : 484|1@0+ (1,0) [0|200000] "" XXX

 SG_ REL_ACCEL3 : 207|6@0+ (1,0) [0|200000] "" XXX
 SG_ FOURTH3: 200|13@0+ (1,0) [0|200000] "" XXX
 SG_ LEAD_DIST3 : 226|12@0+ (0.1,0) [0|200000] "" XXX
 SG_ REL_VEL3 : 245|13@0+ (1,0) [0|200000] "" XXX

 SG_ REL_ACCEL4 : 279|6@0+ (1,0) [0|200000] "" XXX
 SG_ FOURTH4: 272|13@0+ (1,0) [0|200000] "" XXX
 SG_ LEAD_DIST4 : 298|12@0+ (0.1,0) [0|200000] "" XXX
 SG_ REL_VEL4 : 317|13@0+ (1,0) [0|200000] "" XXX

 SG_ REL_ACCEL5 : 351|6@0+ (1,0) [0|200000] "" XXX
 SG_ FOURTH5: 344|13@0+ (1,0) [0|200000] "" XXX
 SG_ LEAD_DIST5 : 370|12@0+ (0.1,0) [0|200000] "" XXX
 SG_ REL_VEL5 : 389|13@0+ (1,0) [0|200000] "" XXX

 SG_ REL_ACCEL6 : 423|6@0+ (1,0) [0|200000] "" XXX
 SG_ FOURTH6: 416|13@0+ (1,0) [0|200000] "" XXX
 SG_ LEAD_DIST6 : 442|12@0+ (0.1,0) [0|200000] "" XXX
 SG_ REL_VEL6 : 461|13@0+ (1,0) [0|200000] "" XXX

//BO_ 407 COMPLEX_SENSOR_3: 64 XXX
 //SG_ REPEATED_NON_DECREASING : 39|18@0+ (1,0) [0|200000] "" XXX

BO_ 427 ACCEL_STEER: 64 XXX
 SG_ MYSTERY_STATE : 52|4@0+ (1,0) [0|16] "" XXX
 SG_ STEERING_RATE : 63|7@0+ (1,-75) [0|40000] "" XXX
 SG_ STEER_ANGLE : 71|12@0+ (1,-1500) [0|4000] "" XXX
 SG_ ACCEL_X : 231|12@0+ (0.1,-2000) [0|4000] "" XXX
 SG_ ACCEL_X_REPEAT : 235|12@0+ (0.1,-2000) [0|4000] "" XXX
 SG_ YAW : 255|12@0+ (0.1,-2000) [0|4000] "" XXX
 SG_ YAW_REPEAT : 259|12@0+ (0.1,-2000) [0|4000] "" XXX
 SG_ STEER_ANGLE_REPEAT : 315|12@0+ (1,-3050) [0|4000] "" XXX
 SG_ STEER_ANGLE_BUT_NOT : 343|15@0+ (1,0) [0|40000] "" XXX
 SG_ MYSTERY_STATE2 : 344|1@0+ (1,0) [0|1] "" XXX
 SG_ STEER_ANGLE_REPEAT_AGAIN : 359|11@0+ (1,-1000) [0|2000] "" XXX

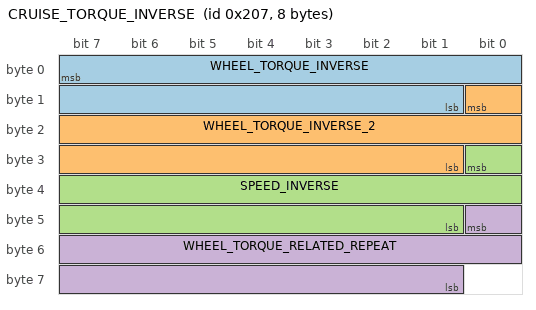
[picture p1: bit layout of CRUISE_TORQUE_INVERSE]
BO_ 519 CRUISE_TORQUE_INVERSE: 8 XXX
 SG_ WHEEL_TORQUE_INVERSE : 7|15@0+ (1,0) [0|2000] "" XXX
 SG_ WHEEL_TORQUE_INVERSE_2 : 8|16@0+ (1,0) [0|20000] "" XXX
 SG_ SPEED_INVERSE : 24|16@0+ (1,0) [0|60000] "" XXX
 SG_ WHEEL_TORQUE_RELATED_REPEAT : 40|16@0+ (1,0) [0|60000] "" XXX

BO_ 534 BUTTONS_1: 4 XXX
 SG_ SOMETHING_MOSTLY_ON: 23|1@0+ (1,0) [0|1] "" XXX
 SG_ DISCRETE_LOW_SPEEDS : 28|4@0+ (1,0) [0|8] "" XXX

BO_ 544 BRAKE_ENGINE: 3 XXX
 SG_ STOPPED_STATE : 22|1@0+ (1,0) [0|1] "" XXX

BO_ 548 BRAKE: 7 XXX
 SG_ BRAKE_STATE : 7|5@0+ (1,0) [0|1024] "" XXX
 SG_ BRAKE_PEDAL : 2|10@0+ (1,0) [0|1024] "" XXX

BO_ 550 WHEEL_ENCODERS: 64 XXX
 SG_ WHEEL_SPEED_FL : 111|16@0+ (0.0057,0) [0|65535] "" XXX
 SG_ WHEEL_SPEED_FR : 127|16@0+ (0.0057,0) [0|65535] "" XXX
 SG_ WHEEL_SPEED_FRONT : 143|16@0+ (0.01,0) [0|65535] "" XXX
 SG_ WHEEL_SPEED_RR : 287|16@0+ (0.0057,0) [0|65535] "" XXX
 SG_ WHEEL_SPEED_RL : 303|16@0+ (0.0057,0) [0|65535] "" XXX
 SG_ WHEEL_SPEED_REAR : 319|16@0+ (0.01,0) [0|65535] "" XXX

BO_ 771 SONAR : 64 XXX
 SG_ SONAR1 : 135|6@0+ (0.0833,0) [0|300] "" XXX
 SG_ SONAR2 : 143|6@0+ (0.0833,0) [0|300] "" XXX
 SG_ SONAR3 : 151|6@0+ (0.0833,0) [0|300] "" XXX
 SG_ SONAR4 : 159|6@0+ (0.0833,0) [0|300] "" XXX
 SG_ SONAR5 : 167|6@0+ (0.0833,0) [0|300] "" XXX
 SG_ SONAR6 : 175|6@0+ (0.0833,0) [0|300] "" XXX

 SG_ SONAR7 : 223|6@0+ (0.0833,0) [0|300] "" XXX
 SG_ SONAR8 : 231|6@0+ (0.0833,0) [0|300] "" XXX
 SG_ SONAR9 : 239|6@0+ (0.0833,0) [0|300] "" XXX
 SG_ SONAR10 : 247|6@0+ (0.0833,0) [0|300] "" XXX
 SG_ SONAR11 : 255|6@0+ (0.0833,0) [0|300] "" XXX
 SG_ SONAR12 : 263|6@0+ (0.0833,0) [0|300] "" XXX

 SG_ SONAR13 : 311|6@0+ (0.0833,0) [0|300] "" XXX
 SG_ SONAR14 : 319|6@0+ (0.0833,0) [0|300] "" XXX
 SG_ SONAR15 : 327|6@0+ (0.0833,0) [0|300] "" XXX
 SG_ SONAR16 : 335|6@0+ (0.0833,0) [0|300] "" XXX
 SG_ SONAR17 : 343|6@0+ (0.0833,0) [0|300] "" XXX
 SG_ SONAR18 : 351|6@0+ (0.0833,0) [0|300] "" XXX
 SG_ SONAR19 : 359|6@0+ (0.0833,0) [0|300] "" XXX
 SG_ SONAR20 : 367|6@0+ (0.0833,0) [0|300] "" XXX

 //SG_ GEAR : 219|3@0+ (1,0) [0|8] "" XXX
 //SG_ DRIVE : 419|1@0+ (1,0) [0|1] "" XXX

BO_ 768 STEER_TORQUE_SENSOR2: 2 XXX
 SG_ STEERING_TORQUE : 6|7@0+ (1,0) [0|127] "" XXX
 SG_ STEERING_PRESSED : 15|1@0+ (-1,1) [0|7] "" XXX

//BO_ 783 CRUISE_STATE: 3 XXX
// SG_ CRUISE_ENABLED : 3|1@0+ (1,0) [0|1] "" XXX

BO_ 779 BONUS_RADAR1: 64 XXX
 SG_ SIG1 : 38|12@0+ (1,0) [0|1000] "" XXX
 SG_ SIG2 : 53|8@0+ (1,0) [0|1000] "" XXX
 SG_ SIG3 : 70|8@0+ (1,0) [0|1000] "" XXX
 SG_ SIG4 : 78|9@0+ (1,0) [0|1000] "" XXX

BO_ 783 BONUS_RADAR2: 64 XXX
 SG_ SIG1 : 38|12@0+ (1,0) [0|1000] "" XXX
 SG_ SIG2 : 53|8@0+ (1,0) [0|1000] "" XXX
 SG_ SIG3 : 70|8@0+ (1,0) [0|1000] "" XXX
 SG_ SIG4 : 78|9@0+ (1,0) [0|1000] "" XXX

BO_ 875 EightSevenFive: 32 XXX
 SG_ NOISY : 157|6@0+ (1,0) [0|100] "" XXX
 SG_ ANGLES : 224|10@0+ (1,0) [0|100] "" XXX

BO_ 888 EightEightEight: 32 XXX
 SG_ SEISMIC_NOISY_120 : 157|6@0+ (1,0) [0|100] "" XXX
 SG_ ANGLES : 224|10@0+ (1,0) [0|100] "" XXX

BO_ 923 SIDE_RADAR1: 64 XXX
 SG_ SIG1_LEAD : 267|9@0+ (0.2,0) [0|1000] "" XXX
 SG_ SIG2_VEL : 274|16@0+ (0.01,0) [0|1000] "" XXX
 SG_ SIG3_ANGLEH : 301|12@0+ (0.01,0) [0|1000] "" XXX
 SG_ SIG4_ANGLEV : 305|9@0+ (0.2,0) [0|1000] "" XXX

BO_ 924 SIDE_RADAR2: 64 XXX
 SG_ SIG1_LEAD : 385|9@0+ (0.2,0) [0|1000] "" XXX
 SG_ SIG2_VEL : 392|16@0+ (0.01,0) [0|1000] "" XXX
 SG_ SIG3_ANGLEH : 419|12@0+ (0.01,0) [0|1000] "" XXX
 SG_ SIG4_ANGLEV : 439|9@0+ (0.2,0) [0|1000] "" XXX

BO_ 936 SIDE_RADAR3: 64 XXX
 SG_ SIG1_LEAD : 31|9@0+ (0.2,0) [0|1000] "" XXX
 SG_ SIG2_VEL : 38|16@0+ (0.01,0) [0|1000] "" XXX
 SG_ SIG3_ANGLEH : 49|12@0+ (0.01,0) [0|1000] "" XXX
 SG_ SIG4_ANGLEV : 69|9@0+ (0.2,0) [0|1000] "" XXX

BO_ 951 SIDE_RADAR4: 64 XXX
 SG_ SIG1_LEAD : 267|9@0+ (0.2,0) [0|1000] "" XXX
 SG_ SIG2_VEL : 274|16@0+ (0.01,0) [0|1000] "" XXX
 SG_ SIG3_ANGLEH : 301|12@0+ (0.01,0) [0|1000] "" XXX
 SG_ SIG4_ANGLEV : 305|9@0+ (0.2,0) [0|1000] "" XXX

BO_ 954 SIDE_RADAR5: 64 XXX
 SG_ SIG1_LEAD : 385|9@0+ (0.2,0) [0|1000] "" XXX
 SG_ SIG2_VEL : 392|16@0+ (0.01,0) [0|1000] "" XXX
 SG_ SIG3_ANGLEH : 419|12@0+ (0.01,0) [0|1000] "" XXX
 SG_ SIG4_ANGLEV : 439|9@0+ (0.2,0) [0|1000] "" XXX

BO_ 958 SIDE_RADAR6: 64 XXX
 SG_ SIG1_LEAD : 31|9@0+ (0.2,0) [0|1000] "" XXX
 SG_ SIG2_VEL : 38|16@0+ (0.01,0) [0|1000] "" XXX
 SG_ SIG3_ANGLEH : 49|12@0+ (0.01,0) [0|1000] "" XXX
 SG_ SIG4_ANGLEV : 69|9@0+ (0.2,0) [0|1000] "" XXX

BO_ 1018 SPEED2: 32 XXX
 SG_ SPEED : 37|10@0+ (1,0) [0|1000] "" XXX
 SG_ SPEED2 : 52|9@0+ (1,0) [0|1000] "" XXX
 SG_ INTERESTING_DECREASING_SIGNAL : 172|12@0+ (1,0) [0|1000] "" XXX
 SG_ BRAKE_ON : 234|1@0+ (1,0) [0|1] "" XXX
 SG_ ANOTHER_STATE : 233|1@0+ (1,0) [0|1] "" XXX
 SG_ COUNTER : 247|2@0+ (1,0) [0|3] "" XXX

BO_ 1055 GEARBOX: 2 XXX
 SG_ SPORTS_MODE : 13|1@0+ (1,0) [0|1] "" XXX
 SG_ GEAR_SHIFTER : 5|3@0+ (1,0) [0|255] "" XXX

BO_ 1081 ODOMETER: 6 XXX
 SG_ UNKNOWN1 : 7|8@0+ (1,-75) [0|200] "" XXX
 SG_ ODOMETER : 23|20@0+ (1,0) [0|1000000] "m" XXX

BO_ 1105 UNKNOWN_STATE : 24 XXX
 SG_ MYSTERY_NOISY_DISCRETE_STATE : 68|7@0+ (1,0) [0|100] "" XXX
 SG_ SPEEDOMETER : 72|8@0+ (1,0) [0|100] "" XXX

BO_ 1107 ELEVENOHSEVEN: 12 XXX
 SG_ SIGNAL1 : 43|1@0+ (1,0) [0|1] "" XXX
 SG_ SIGNAL2 : 48|9@0+ (1,0) [0|200] "" XXX
 SG_ SIGNAL2_REPEAT : 72|9@0+ (1,0) [0|200] "" XXX

BO_ 1119 WHEEL_BUTTONS: 20 XXX
 SG_ SIGNAL1 : 48|3@0+ (1,0) [0|1] "" XXX
 SG_ LKAS_LDW_ON : 55|1@0+ (1,0) [0|1] "" XXX
 SG_ ACC_BTNS : 61|3@0+ (1,0) [0|1] "" XXX

BO_ 1137 UNKNOWN_247: 8 XXX
 SG_ UNKNOWN2: 40|6@0+ (1,0) [0|1] "" XXX
 SG_ UNKNOWN1: 48|6@0+ (1,0) [0|1] "" XXX

BO_ 1356 LKAS_SETTINGS_2: 8 XXX
 SG_ TWO_BIT_STATE : 45|2@0+ (1,0) [0|3] "" XXX

BO_ 1487 ACC_HUD: 48 XXX
 SG_ SYSTEM_ON : 94|1@0+ (1,0) [0|1] "" XXX
 SG_ MINICAR : 142|1@0+ (1,0) [0|1] "" XXX
 //SG_ HUD_STATE1 : 153|2@0+ (1,0) [0|4] "" XXX
 SG_ SET_SPEED : 158|7@0+ (1,0) [0|90] "" XXX
 //lsb is sysetm on/off
 SG_ SET_DISTANCE : 166|2@0+ (1,0) [0|3] "" XXX
 SG_ HUD_STATES : 177|5@0+ (1,0) [0|32] "" XXX
 SG_ STATE_SIGNAL : 287|4@0+ (1,0) [0|16] "" XXX

BO_ 1459 GEAR: 4 XXX
 SG_ REVERSE : 8|1@0+ (1,0) [0|1] "" XXX

BO_ 1687 SOMETHING_INTERESTING: 16 XXX
 SG_ MY_SIGNAL : 46|6@0+ (1,0) [0|1000] "" XXX

BO_ 1693 SOMETHING_SIGNED: 16 XXX
 SG_ OVERFLOW : 46|6@0+ (1,0) [0|1000] "" XXX

VAL_ 1119 ACC_BTNS 0 "none" 1 "resume" 2 "set" 3 "distance" 4 "cancel" 5 "system_toggle";
VAL_ 308 CRUISE_STATE 1 "off" 9 "hold_waiting_user_cmd" 13 "disabled" 25 "enabled" 29 "unknown"
////VAL_ 921 CRUISE_CONTROL_STATE 2 "disabled" 11 "hold" 10 "hold_waiting_user_cmd" 6 "enabled" 5 "faulted" 0 "off";
